# MM32SPINxxxx register map
Vendor: MindMotion Ltd.; Series: MM32SPIN; File version: 1.4
CPU: CM0 r0p0, little endian, no MPU, no FPU, 3 interrupt priority bits
Registers are 32-bit, read-write, reset 0x0 unless marked. A register's access mark holds for its fields unless they carry their own. Offsets are from the block's base; [hi:lo] are bit positions; {n}, {i} and the like mark numbered series.

## CAN — Controller area network
Base 0x40006400
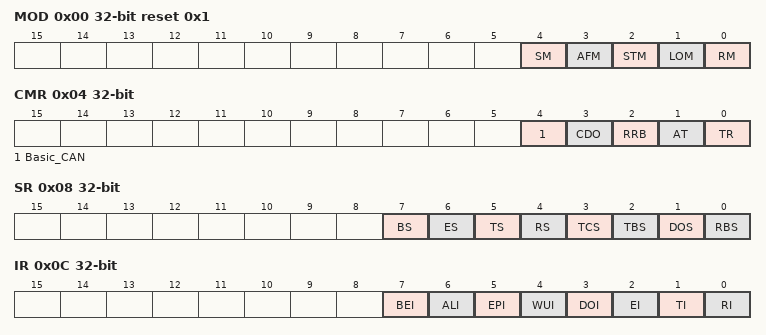
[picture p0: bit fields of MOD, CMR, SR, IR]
0x00 MOD reset 0x1
  [4] SM — *D4
  [3] AFM — Acceptance filter mode
  [2] STM — Self test mode
  [1] LOM — Listen only mode
  [0] RM — Reset mode
0x04 CMR
  [4] Basic_CAN
  [3] CDO — Clear data overrun
  [2] RRB — Release receive buffer
  [1] AT — Abort transmission
  [0] TR — Transmission request
0x08 SR
  [7] BS — Bus status
  [6] ES — Error status
  [5] TS — Transmit status
  [4] RS — Receive status
  [3] TCS — Transmission complete status
  [2] TBS — Transmit buffer status
  [1] DOS — Data overrun status
  [0] RBS — Receive buffer status
0x0C IR ro
  [7] BEI
  [6] ALI
  [5] EPI
  [4] WUI — Wake-up interrupt
  [3] DOI — Data overrun interrupt
  [2] EI — Error interrupt
  [1] TI — Transmit interrupt
  [0] RI — Receive interrupt
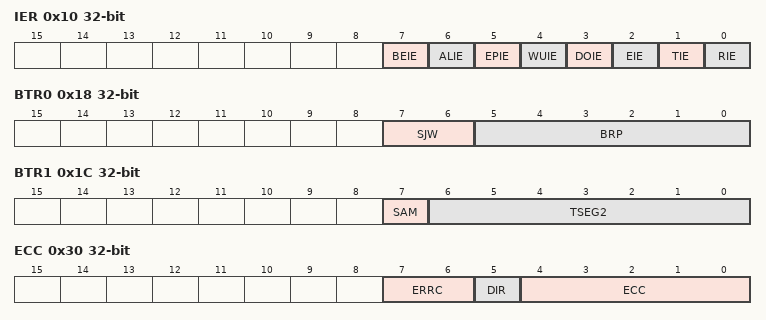
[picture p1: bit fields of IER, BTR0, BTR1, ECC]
0x10 IER
  [7] BEIE — Bus error interrupt enable
  [6] ALIE — Arbitration lost interrupt enable
  [5] EPIE — Error passive interrupt enable
  [4] WUIE — Wake up interrupt enable
  [3] DOIE — Data overrun interrupt enable
  [2] EIE — Error interrupt enable
  [1] TIE — Transmit interrupt enable
  [0] RIE — Receive interrupt enable
0x14 AMR
  [7:0] AM — Acceptance mask
0x18 BTR0
  [7:6] SJW — Synchronization jump width
  [5:0] BRP — Baud rate prescaler
0x1C BTR1
  [7] SAM — Sampling
  [6:0] TSEG2 — Time segment 2
0x2C ALC
  [4:0] BITNO — Bitnumber
0x30 ECC ro
  [7:6] ERRC — Error code
  [5] DIR — Direction
  [4:0] ECC — Error code capture
0x34 EWLR reset 0x96
  [7:0] EWL — Programmable error warning limit
0x38 RXERR
  [7:0] RXERR — RX error counter register
0x3C TXERR
  [7:0] TXERR — TX error counter register
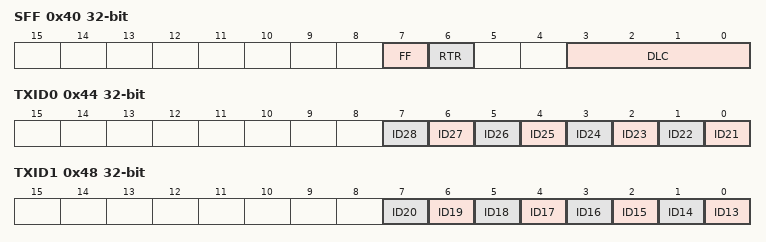
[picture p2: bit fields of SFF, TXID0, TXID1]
0x40 SFF
  [7] FF — Frame format
  [6] RTR — Remote transmission request
  [3:0] DLC — Data length code bit
0x44 TXID0
  [n-21] ID{n} (n=21..28) — Identifier bit {n}
0x48 TXID1
  [n-13] ID{n} (n=13..20) — Identifier bit {n}
0x4C TXDATA0
  [7:0] DATA0
0x50 TXDATA1
  [7:0] DATA1
0x7C CDR
  [7] MODE — CAN mode

## GPIOA — General purpose I/O
Base 0x48000000
Same registers: GPIOB 0x48000400, GPIOC 0x48000800, GPIOD 0x48000C00
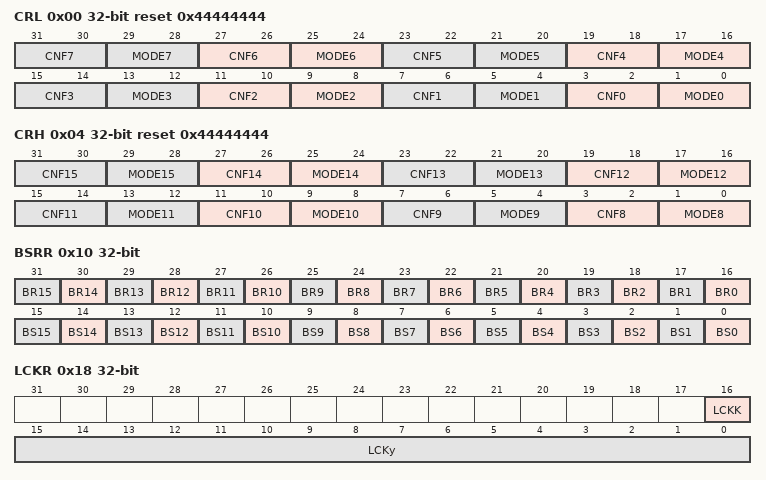
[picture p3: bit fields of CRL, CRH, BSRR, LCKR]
0x00 CRL reset 0x44444444
  [4n+3:4n+2] CNF{n} (n=0..7) — Port {n} configuration bits
  [4n+1:4n] MODE{n} (n=0..7) — Port {n} mode bits
0x04 CRH reset 0x44444444
  [4n-29:4n-30] CNF{n} (n=8..15) — Port {n} configuration bits
  [4n-31:4n-32] MODE{n} (n=8..15) — Port {n} mode bits
0x08 IDR ro
  [15:0] IDRy — Port input data
0x0C ODR
  [15:0] ODRy — Port output data
0x10 BSRR wo
  [n+16] BR{n} (n=0..15) — Port A Reset bit {n}
  [n] BS{n} (n=0..15) — Port A Set bit {n}
0x14 BRR wo
  [15:0] BRy — Port A Reset bit y
0x18 LCKR
  [16] LCKK — Lock key
  [15:0] LCKy — Port A Lock bit y
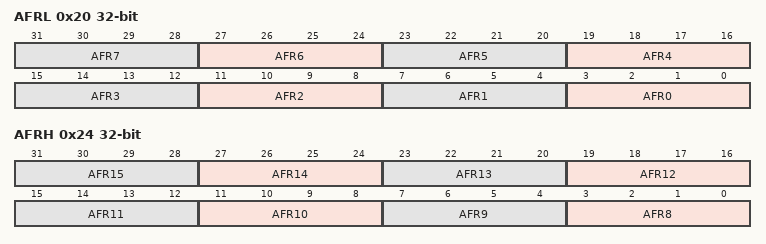
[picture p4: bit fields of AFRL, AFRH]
0x20 AFRL
  [4n+3:4n] AFR{n} (n=0..7)
0x24 AFRH
  [4n-29:4n-32] AFR{n} (n=8..15)

## SYSCFG
Base 0x40010000
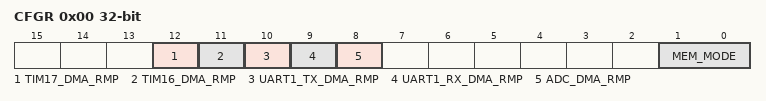
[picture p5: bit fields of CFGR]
0x00 CFGR
  [12] TIM17_DMA_RMP, [11] TIM16_DMA_RMP, [10] UART1_TX_DMA_RMP, [9] UART1_RX_DMA_RMP, [8] ADC_DMA_RMP, [1:0] MEM_MODE
{0x4+4i} EXTICR{i} (i=1..4)
  [15:0] EXTI{4i-1}

## EXTI
Base 0x40010400
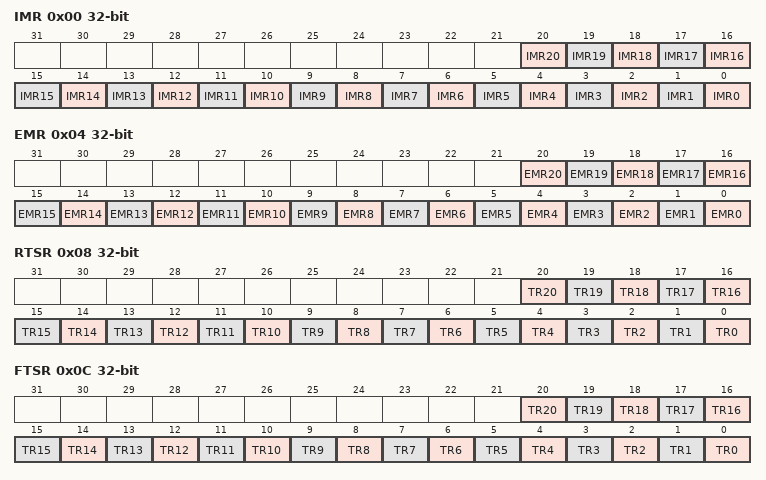
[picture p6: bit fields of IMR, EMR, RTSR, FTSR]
0x00 IMR
  [n] IMR{n} (n=0..20) — Interrupt Mask on line {n}
0x04 EMR
  [n] EMR{n} (n=0..20) — Event Mask on line {n}
0x08 RTSR
  [n] TR{n} (n=0..20) — Rising trigger event configuration bit of line {n}
0x0C FTSR
  [n] TR{n} (n=0..20) — Falling trigger event configuration bit of line {n}
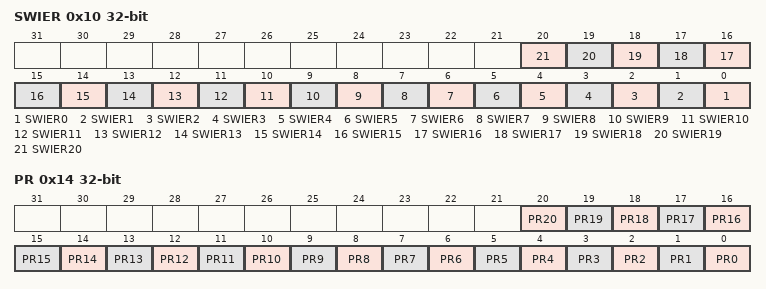
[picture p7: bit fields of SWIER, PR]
0x10 SWIER
  [n] SWIER{n} (n=0..20) — Software interrupt on line {n}
0x14 PR
  [n] PR{n} (n=0..20) — Pending bit

## DMA — DMA controller
Base 0x40020000
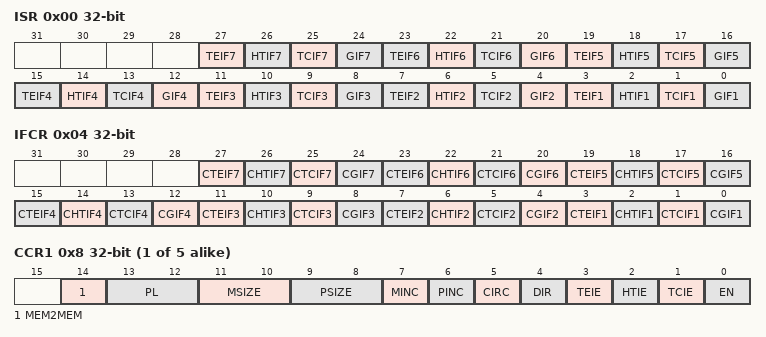
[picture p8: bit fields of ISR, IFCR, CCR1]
0x00 ISR ro
  [4n-1] TEIF{n} (n=1..7) — channel {n} transfer error flag
  [4n-2] HTIF{n} (n=1..7) — channel {n} half transfer flag
  [4n-3] TCIF{n} (n=1..7) — channel {n} half complete flag
  [4n-4] GIF{n} (n=1..7) — channel {n} global interrupt flag
0x04 IFCR ro
  [4n-1] CTEIF{n} (n=1..7) — channel {n} transfer error clear
  [4n-2] CHTIF{n} (n=1..7) — channel {n} half transfer clear
  [4n-3] CTCIF{n} (n=1..7) — channel {n} half complete clear
  [4n-4] CGIF{n} (n=1..7) — channel {n} global interrupt clear
{0x4+4i} CCR{i} (i=1..5)
  [14] MEM2MEM — Memory to memory mode
  [13:12] PL — Channel priority level
  [11:10] MSIZE — Memory size
  [9:8] PSIZE — Peripheral size
  [7] MINC — Memory increment mode
  [6] PINC — Peripheral increment mode
  [5] CIRC — Circular mode
  [4] DIR — Data transfer direction
  [3] TEIE — Transfer error interrupt enable
  [2] HTIE — Half transfer interrupt enable
  [1] TCIE — Transfer complete interrupt enable
  [0] EN — Channel enable
{0x18+4i} CNDTR{i} (i=1..5)
  [15:0] NDT — Number of data to transfer
{0x2C+4i} CPAR{i} (i=1..5)
  [31:0] PA — Peripheral address
{0x40+4i} CMAR{i} (i=1..5)
  [31:0] MA — Memory address
